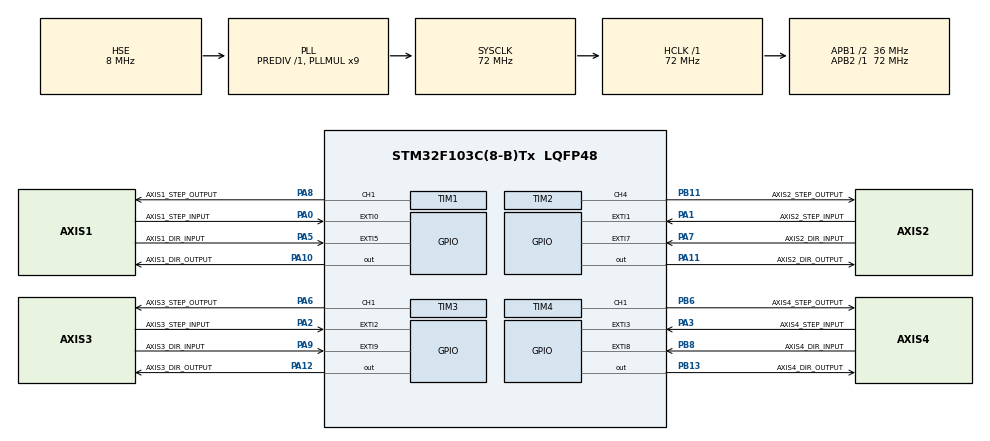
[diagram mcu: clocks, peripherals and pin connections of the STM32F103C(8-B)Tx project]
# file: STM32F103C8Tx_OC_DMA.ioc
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Dma.Request0=TIM3_CH1/TRIG
Dma.Request1=TIM4_CH1
Dma.Request2=TIM1_CH1
Dma.Request3=TIM2_CH2/CH4
Dma.TIM1_CH1.2.Direction=DMA_MEMORY_TO_PERIPH
Dma.TIM1_CH1.2.Instance=DMA1_Channel2
Dma.TIM1_CH1.2.MemDataAlignment=DMA_MDATAALIGN_HALFWORD
Dma.TIM1_CH1.2.MemInc=DMA_MINC_DISABLE
Dma.TIM1_CH1.2.Mode=DMA_NORMAL
Dma.TIM1_CH1.2.PeriphDataAlignment=DMA_PDATAALIGN_HALFWORD
Dma.TIM1_CH1.2.PeriphInc=DMA_PINC_DISABLE
Dma.TIM1_CH1.2.Priority=DMA_PRIORITY_MEDIUM
Dma.TIM2_CH2/CH4.3.Direction=DMA_MEMORY_TO_PERIPH
Dma.TIM2_CH2/CH4.3.Instance=DMA1_Channel7
Dma.TIM2_CH2/CH4.3.MemDataAlignment=DMA_MDATAALIGN_HALFWORD
Dma.TIM2_CH2/CH4.3.MemInc=DMA_MINC_DISABLE
Dma.TIM2_CH2/CH4.3.Mode=DMA_NORMAL
Dma.TIM2_CH2/CH4.3.PeriphDataAlignment=DMA_PDATAALIGN_HALFWORD
Dma.TIM2_CH2/CH4.3.PeriphInc=DMA_PINC_DISABLE
Dma.TIM2_CH2/CH4.3.Priority=DMA_PRIORITY_LOW
Dma.TIM3_CH1/TRIG.0.Direction=DMA_MEMORY_TO_PERIPH
Dma.TIM3_CH1/TRIG.0.Instance=DMA1_Channel6
Dma.TIM3_CH1/TRIG.0.MemDataAlignment=DMA_MDATAALIGN_HALFWORD
Dma.TIM3_CH1/TRIG.0.MemInc=DMA_MINC_DISABLE
Dma.TIM3_CH1/TRIG.0.Mode=DMA_NORMAL
Dma.TIM3_CH1/TRIG.0.PeriphDataAlignment=DMA_PDATAALIGN_HALFWORD
Dma.TIM3_CH1/TRIG.0.PeriphInc=DMA_PINC_DISABLE
Dma.TIM3_CH1/TRIG.0.Priority=DMA_PRIORITY_VERY_HIGH
Dma.TIM4_CH1.1.Direction=DMA_MEMORY_TO_PERIPH
Dma.TIM4_CH1.1.Instance=DMA1_Channel1
Dma.TIM4_CH1.1.MemDataAlignment=DMA_MDATAALIGN_HALFWORD
Dma.TIM4_CH1.1.MemInc=DMA_MINC_DISABLE
Dma.TIM4_CH1.1.Mode=DMA_NORMAL
Dma.TIM4_CH1.1.PeriphDataAlignment=DMA_PDATAALIGN_HALFWORD
Dma.TIM4_CH1.1.PeriphInc=DMA_PINC_DISABLE
Dma.TIM4_CH1.1.Priority=DMA_PRIORITY_HIGH
Mcu.Family=STM32F1
Mcu.Name=STM32F103C(8-B)Tx
Mcu.Package=LQFP48
NVIC.DMA1_Channel1_IRQn=true\:0\:0\:false\:true\:true\:5
NVIC.DMA1_Channel2_IRQn=true\:0\:0\:false\:true\:true\:6
NVIC.DMA1_Channel6_IRQn=true\:0\:0\:false\:true\:true\:7
NVIC.DMA1_Channel7_IRQn=true\:0\:0\:false\:true\:true\:8
NVIC.EXTI0_IRQn=true\:0\:0\:false\:true\:true\:1
NVIC.EXTI1_IRQn=true\:0\:0\:false\:true\:true\:2
NVIC.EXTI2_IRQn=true\:0\:0\:false\:true\:true\:3
NVIC.EXTI3_IRQn=true\:0\:0\:false\:true\:true\:9
NVIC.EXTI9_5_IRQn=true\:0\:0\:false\:true\:true\:4
NVIC.PriorityGroup=NVIC_PRIORITYGROUP_4
PA0-WKUP.GPIO_Label=AXIS1_STEP_INPUT
PA0-WKUP.GPIO_ModeDefaultEXTI=GPIO_MODE_IT_FALLING
PA0-WKUP.GPIO_PuPd=GPIO_PULLDOWN
PA0-WKUP.Signal=GPXTI0
PA1.GPIO_Label=AXIS2_STEP_INPUT
PA1.GPIO_ModeDefaultEXTI=GPIO_MODE_IT_FALLING
PA1.GPIO_PuPd=GPIO_PULLDOWN
PA1.Signal=GPXTI1
PA10.GPIO_Label=AXIS1_DIR_OUTPUT
PA10.GPIO_ModeDefaultOutputPP=GPIO_MODE_OUTPUT_PP
PA10.GPIO_Speed=GPIO_SPEED_FREQ_LOW
PA10.PinState=GPIO_PIN_RESET
PA10.Signal=GPIO_Output
PA11.GPIO_Label=AXIS2_DIR_OUTPUT
PA11.GPIO_ModeDefaultOutputPP=GPIO_MODE_OUTPUT_PP
PA11.GPIO_Speed=GPIO_SPEED_FREQ_LOW
PA11.PinState=GPIO_PIN_RESET
PA11.Signal=GPIO_Output
PA12.GPIO_Label=AXIS3_DIR_OUTPUT
PA12.GPIO_ModeDefaultOutputPP=GPIO_MODE_OUTPUT_PP
PA12.GPIO_Speed=GPIO_SPEED_FREQ_LOW
PA12.PinState=GPIO_PIN_RESET
PA12.Signal=GPIO_Output
PA13.Mode=Serial_Wire
PA13.Signal=SYS_JTMS-SWDIO
PA14.Mode=Serial_Wire
PA14.Signal=SYS_JTCK-SWCLK
PA2.GPIO_Label=AXIS3_STEP_INPUT
PA2.GPIO_ModeDefaultEXTI=GPIO_MODE_IT_FALLING
PA2.GPIO_PuPd=GPIO_PULLDOWN
PA2.Signal=GPXTI2
PA3.GPIO_Label=AXIS4_STEP_INPUT
PA3.GPIO_ModeDefaultEXTI=GPIO_MODE_IT_FALLING
PA3.GPIO_PuPd=GPIO_PULLDOWN
PA3.Signal=GPXTI3
PA5.GPIO_Label=AXIS1_DIR_INPUT
PA5.GPIO_ModeDefaultEXTI=GPIO_MODE_IT_RISING_FALLING
PA5.GPIO_PuPd=GPIO_PULLDOWN
PA5.Signal=GPXTI5
PA6.GPIO_Label=AXIS3_STEP_OUTPUT
PA6.GPIO_Speed=GPIO_SPEED_FREQ_HIGH
PA6.Signal=S_TIM3_CH1
PA7.GPIO_Label=AXIS2_DIR_INPUT
PA7.GPIO_ModeDefaultEXTI=GPIO_MODE_IT_RISING_FALLING
PA7.GPIO_PuPd=GPIO_PULLDOWN
PA7.Signal=GPXTI7
PA8.GPIO_Label=AXIS1_STEP_OUTPUT
PA8.GPIO_Speed=GPIO_SPEED_FREQ_HIGH
PA8.Signal=S_TIM1_CH1
PA9.GPIO_Label=AXIS3_DIR_INPUT
PA9.GPIO_ModeDefaultEXTI=GPIO_MODE_IT_RISING_FALLING
PA9.GPIO_PuPd=GPIO_PULLDOWN
PA9.Signal=GPXTI9
PB11.GPIO_Label=AXIS2_STEP_OUTPUT
PB11.GPIO_ModeDefaultPP=GPIO_MODE_AF_PP
PB11.GPIO_Speed=GPIO_SPEED_FREQ_HIGH
PB11.Signal=S_TIM2_CH4
PB13.GPIO_Label=AXIS4_DIR_OUTPUT
PB13.Signal=GPIO_Output
PB6.GPIO_Label=AXIS4_STEP_OUTPUT
PB6.GPIO_Speed=GPIO_SPEED_FREQ_HIGH
PB6.Signal=S_TIM4_CH1
PB8.GPIO_Label=AXIS4_DIR_INPUT
PB8.GPIO_ModeDefaultEXTI=GPIO_MODE_IT_RISING_FALLING
PB8.GPIO_PuPd=GPIO_PULLDOWN
PB8.Signal=GPXTI8
PD0-OSC_IN.Mode=HSE-External-Oscillator
PD0-OSC_IN.Signal=RCC_OSC_IN
PD1-OSC_OUT.Mode=HSE-External-Oscillator
PD1-OSC_OUT.Signal=RCC_OSC_OUT
ProjectManager.HeapSize=0x200
ProjectManager.StackSize=0x400
ProjectManager.TargetToolchain=SW4STM32
RCC.AHBCLKDivider=RCC_SYSCLK_DIV1
RCC.AHBFreq_Value=72000000
RCC.APB1CLKDivider=RCC_HCLK_DIV2
RCC.APB1Freq_Value=36000000
RCC.APB1TimFreq_Value=72000000
RCC.APB2CLKDivider=RCC_HCLK_DIV1
RCC.APB2Freq_Value=72000000
RCC.APB2TimFreq_Value=72000000
RCC.HCLKFreq_Value=72000000
RCC.OscillatorTypeHSI=RCC_OSCILLATORTYPE_HSI
RCC.PLLMUL=RCC_PLL_MUL9
RCC.PLLSourceVirtual=RCC_PLLSOURCE_HSE
RCC.SYSCLKFreq_VALUE=72000000
RCC.SYSCLKSource=RCC_SYSCLKSOURCE_PLLCLK
RCC.TimSys_Div=SYSTICK_CLKSOURCE_HCLK
RCC.USBFreq_Value=72000000
SH.S_TIM1_CH1.0=TIM1_CH1,Output Compare1 CH1
SH.S_TIM2_CH4.0=TIM2_CH4,Output Compare4 CH4
SH.S_TIM3_CH1.0=TIM3_CH1,Output Compare1 CH1
SH.S_TIM4_CH1.0=TIM4_CH1,Output Compare1 CH1
TIM1.Channel-Output\ Compare1\ CH1=TIM_CHANNEL_1
TIM1.OCIdleState_1=TIM_OCIDLESTATE_RESET
TIM1.OCMode_1=TIM_OCMODE_TOGGLE
TIM1.OCPolarity_1=TIM_OCPOLARITY_HIGH
TIM1.Period=0xFFFF
TIM1.Prescaler=0xFFFF
TIM1.Pulse-Output\ Compare1\ CH1=0xFFFF
TIM1.TIM_MasterOutputTrigger=TIM_TRGO_RESET
TIM2.Channel-Output\ Compare4\ CH4=TIM_CHANNEL_4
TIM2.OCMode_4=TIM_OCMODE_TOGGLE
TIM2.OCPolarity_4=TIM_OCPOLARITY_HIGH
TIM2.Period=0xFFFF
TIM2.Prescaler=0xFFFF
TIM2.Pulse-Output\ Compare4\ CH4=0xFFFF
TIM2.TIM_MasterOutputTrigger=TIM_TRGO_RESET
TIM3.Channel-Output\ Compare1\ CH1=TIM_CHANNEL_1
TIM3.OCMode_1=TIM_OCMODE_TOGGLE
TIM3.OCPolarity_1=TIM_OCPOLARITY_HIGH
TIM3.Period=0xFFFF
TIM3.Prescaler=0xFFFF
TIM3.Pulse-Output\ Compare1\ CH1=0xFFFF
TIM3.TIM_MasterOutputTrigger=TIM_TRGO_RESET
TIM4.Channel-Output\ Compare1\ CH1=TIM_CHANNEL_1
TIM4.OCMode_1=TIM_OCMODE_TOGGLE
TIM4.OCPolarity_1=TIM_OCPOLARITY_HIGH
TIM4.Period=0xFFFF
TIM4.Prescaler=0xFFFF
TIM4.Pulse-Output\ Compare1\ CH1=0xFFFF
TIM4.TIM_MasterOutputTrigger=TIM_TRGO_RESET
VP_TIM1_VS_ClockSourceINT.Mode=Internal
VP_TIM2_VS_ClockSourceINT.Mode=Internal
VP_TIM3_VS_ClockSourceINT.Mode=Internal
VP_TIM4_VS_ClockSourceINT.Mode=Internal
board=STM32F103C8Tx_OC_DMA

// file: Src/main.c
/**
  ******************************************************************************
  * File Name          : main.c
  * Description        : Main program body
  ******************************************************************************
  ** This notice applies to any and all portions of this file
  * that are not between comment pairs USER CODE BEGIN and
  * USER CODE END. Other portions of this file, whether
  * inserted by the user or by software development tools
  * are owned by their respective copyright owners.
  *
  * COPYRIGHT(c) 2017 STMicroelectronics
  *
  * Redistribution and use in source and binary forms, with or without modification,
  * are permitted provided that the following conditions are met:
  *   1. Redistributions of source code must retain the above copyright notice,
  *      this list of conditions and the following disclaimer.
  *   2. Redistributions in binary form must reproduce the above copyright notice,
  *      this list of conditions and the following disclaimer in the documentation
  *      and/or other materials provided with the distribution.
  *   3. Neither the name of STMicroelectronics nor the names of its contributors
  *      may be used to endorse or promote products derived from this software
  *      without specific prior written permission.
  *
  * THIS SOFTWARE IS PROVIDED BY THE COPYRIGHT HOLDERS AND CONTRIBUTORS "AS IS"
  * AND ANY EXPRESS OR IMPLIED WARRANTIES, INCLUDING, BUT NOT LIMITED TO, THE
  * IMPLIED WARRANTIES OF MERCHANTABILITY AND FITNESS FOR A PARTICULAR PURPOSE ARE
  * DISCLAIMED. IN NO EVENT SHALL THE COPYRIGHT HOLDER OR CONTRIBUTORS BE LIABLE
  * FOR ANY DIRECT, INDIRECT, INCIDENTAL, SPECIAL, EXEMPLARY, OR CONSEQUENTIAL
  * DAMAGES (INCLUDING, BUT NOT LIMITED TO, PROCUREMENT OF SUBSTITUTE GOODS OR
  * SERVICES; LOSS OF USE, DATA, OR PROFITS; OR BUSINESS INTERRUPTION) HOWEVER
  * CAUSED AND ON ANY THEORY OF LIABILITY, WHETHER IN CONTRACT, STRICT LIABILITY,
  * OR TORT (INCLUDING NEGLIGENCE OR OTHERWISE) ARISING IN ANY WAY OUT OF THE USE
  * OF THIS SOFTWARE, EVEN IF ADVISED OF THE POSSIBILITY OF SUCH DAMAGE.
  *
  ******************************************************************************
  */
#include "main.h"
#include "stm32f1xx_hal.h"

TIM_HandleTypeDef htim1;
TIM_HandleTypeDef htim2;
TIM_HandleTypeDef htim3;
TIM_HandleTypeDef htim4;
DMA_HandleTypeDef hdma_tim1_ch1;
DMA_HandleTypeDef hdma_tim2_ch2_ch4;
DMA_HandleTypeDef hdma_tim3_ch1_trig;
DMA_HandleTypeDef hdma_tim4_ch1;

void SystemClock_Config(void);
static void MX_GPIO_Init(void);
static void MX_DMA_Init(void);
static void MX_TIM1_Init(void);
static void MX_TIM2_Init(void);
static void MX_TIM3_Init(void);
static void MX_TIM4_Init(void);
static void MX_NVIC_Init(void);
void HAL_TIM_MspPostInit(TIM_HandleTypeDef *htim);

/* USER CODE BEGIN PFP */
void setup_out_timers_2();
/* USER CODE END PFP */

int main(void)
{

  /* MCU Configuration----------------------------------------------------------*/

  /* Reset of all peripherals, Initializes the Flash interface and the Systick. */
  HAL_Init();

  /* Configure the system clock */
  SystemClock_Config();

  /* Initialize all configured peripherals */
  MX_GPIO_Init();
  MX_DMA_Init();
  MX_TIM1_Init();
  MX_TIM2_Init();
  MX_TIM3_Init();
  MX_TIM4_Init();

  /* Initialize interrupts */
  MX_NVIC_Init();

  /* USER CODE BEGIN 2 */
  setup_out_timers_2();
  /* USER CODE END 2 */

  /* Infinite loop */
  while (1)
  {

  }

}

/** System Clock Configuration
*/
void SystemClock_Config(void)
{

  RCC_OscInitTypeDef RCC_OscInitStruct;
  RCC_ClkInitTypeDef RCC_ClkInitStruct;

    /**Initializes the CPU, AHB and APB busses clocks
    */
  RCC_OscInitStruct.OscillatorType = RCC_OSCILLATORTYPE_HSI|RCC_OSCILLATORTYPE_HSE;
  RCC_OscInitStruct.HSEState = RCC_HSE_ON;
  RCC_OscInitStruct.HSEPredivValue = RCC_HSE_PREDIV_DIV1;
  RCC_OscInitStruct.HSIState = RCC_HSI_ON;
  RCC_OscInitStruct.PLL.PLLState = RCC_PLL_ON;
  RCC_OscInitStruct.PLL.PLLSource = RCC_PLLSOURCE_HSE;
  RCC_OscInitStruct.PLL.PLLMUL = RCC_PLL_MUL9;
  if (HAL_RCC_OscConfig(&RCC_OscInitStruct) != HAL_OK)
  {
    _Error_Handler(__FILE__, __LINE__);
  }

    /**Initializes the CPU, AHB and APB busses clocks
    */
  RCC_ClkInitStruct.ClockType = RCC_CLOCKTYPE_HCLK|RCC_CLOCKTYPE_SYSCLK
                              |RCC_CLOCKTYPE_PCLK1|RCC_CLOCKTYPE_PCLK2;
  RCC_ClkInitStruct.SYSCLKSource = RCC_SYSCLKSOURCE_PLLCLK;
  RCC_ClkInitStruct.AHBCLKDivider = RCC_SYSCLK_DIV1;
  RCC_ClkInitStruct.APB1CLKDivider = RCC_HCLK_DIV2;
  RCC_ClkInitStruct.APB2CLKDivider = RCC_HCLK_DIV1;

  if (HAL_RCC_ClockConfig(&RCC_ClkInitStruct, FLASH_LATENCY_2) != HAL_OK)
  {
    _Error_Handler(__FILE__, __LINE__);
  }

    /**Configure the Systick interrupt time
    */
  HAL_SYSTICK_Config(HAL_RCC_GetHCLKFreq()/1000);

    /**Configure the Systick
    */
  HAL_SYSTICK_CLKSourceConfig(SYSTICK_CLKSOURCE_HCLK);

  /* SysTick_IRQn interrupt configuration */
  HAL_NVIC_SetPriority(SysTick_IRQn, 0, 0);
}

/** NVIC Configuration
*/
static void MX_NVIC_Init(void)
{
  /* EXTI0_IRQn interrupt configuration */
  HAL_NVIC_SetPriority(EXTI0_IRQn, 0, 0);
  HAL_NVIC_EnableIRQ(EXTI0_IRQn);
  /* EXTI1_IRQn interrupt configuration */
  HAL_NVIC_SetPriority(EXTI1_IRQn, 0, 0);
  HAL_NVIC_EnableIRQ(EXTI1_IRQn);
  /* EXTI2_IRQn interrupt configuration */
  HAL_NVIC_SetPriority(EXTI2_IRQn, 0, 0);
  HAL_NVIC_EnableIRQ(EXTI2_IRQn);
  /* EXTI9_5_IRQn interrupt configuration */
  HAL_NVIC_SetPriority(EXTI9_5_IRQn, 0, 0);
  HAL_NVIC_EnableIRQ(EXTI9_5_IRQn);
  /* DMA1_Channel1_IRQn interrupt configuration */
  HAL_NVIC_SetPriority(DMA1_Channel1_IRQn, 0, 0);
  HAL_NVIC_EnableIRQ(DMA1_Channel1_IRQn);
  /* DMA1_Channel2_IRQn interrupt configuration */
  HAL_NVIC_SetPriority(DMA1_Channel2_IRQn, 0, 0);
  HAL_NVIC_EnableIRQ(DMA1_Channel2_IRQn);
  /* DMA1_Channel6_IRQn interrupt configuration */
  HAL_NVIC_SetPriority(DMA1_Channel6_IRQn, 0, 0);
  HAL_NVIC_EnableIRQ(DMA1_Channel6_IRQn);
  /* DMA1_Channel7_IRQn interrupt configuration */
  HAL_NVIC_SetPriority(DMA1_Channel7_IRQn, 0, 0);
  HAL_NVIC_EnableIRQ(DMA1_Channel7_IRQn);
  /* EXTI3_IRQn interrupt configuration */
  HAL_NVIC_SetPriority(EXTI3_IRQn, 0, 0);
  HAL_NVIC_EnableIRQ(EXTI3_IRQn);
}

/* TIM1 init function */
static void MX_TIM1_Init(void)
{

  TIM_ClockConfigTypeDef sClockSourceConfig;
  TIM_MasterConfigTypeDef sMasterConfig;
  TIM_OC_InitTypeDef sConfigOC;
  TIM_BreakDeadTimeConfigTypeDef sBreakDeadTimeConfig;

  htim1.Instance = TIM1;
  htim1.Init.Prescaler = 0xFFFF;
  htim1.Init.CounterMode = TIM_COUNTERMODE_UP;
  htim1.Init.Period = 0xFFFF;
  htim1.Init.ClockDivision = TIM_CLOCKDIVISION_DIV1;
  htim1.Init.RepetitionCounter = 0;
  if (HAL_TIM_Base_Init(&htim1) != HAL_OK)
  {
    _Error_Handler(__FILE__, __LINE__);
  }

  sClockSourceConfig.ClockSource = TIM_CLOCKSOURCE_INTERNAL;
  if (HAL_TIM_ConfigClockSource(&htim1, &sClockSourceConfig) != HAL_OK)
  {
    _Error_Handler(__FILE__, __LINE__);
  }

  if (HAL_TIM_OC_Init(&htim1) != HAL_OK)
  {
    _Error_Handler(__FILE__, __LINE__);
  }

  sMasterConfig.MasterOutputTrigger = TIM_TRGO_RESET;
  sMasterConfig.MasterSlaveMode = TIM_MASTERSLAVEMODE_DISABLE;
  if (HAL_TIMEx_MasterConfigSynchronization(&htim1, &sMasterConfig) != HAL_OK)
  {
    _Error_Handler(__FILE__, __LINE__);
  }

  sConfigOC.OCMode = TIM_OCMODE_TOGGLE;
  sConfigOC.Pulse = 0xFFFF;
  sConfigOC.OCPolarity = TIM_OCPOLARITY_HIGH;
  sConfigOC.OCNPolarity = TIM_OCNPOLARITY_HIGH;
  sConfigOC.OCFastMode = TIM_OCFAST_DISABLE;
  sConfigOC.OCIdleState = TIM_OCIDLESTATE_RESET;
  sConfigOC.OCNIdleState = TIM_OCNIDLESTATE_RESET;
  if (HAL_TIM_OC_ConfigChannel(&htim1, &sConfigOC, TIM_CHANNEL_1) != HAL_OK)
  {
    _Error_Handler(__FILE__, __LINE__);
  }

  sBreakDeadTimeConfig.OffStateRunMode = TIM_OSSR_DISABLE;
  sBreakDeadTimeConfig.OffStateIDLEMode = TIM_OSSI_DISABLE;
  sBreakDeadTimeConfig.LockLevel = TIM_LOCKLEVEL_OFF;
  sBreakDeadTimeConfig.DeadTime = 0;
  sBreakDeadTimeConfig.BreakState = TIM_BREAK_DISABLE;
  sBreakDeadTimeConfig.BreakPolarity = TIM_BREAKPOLARITY_HIGH;
  sBreakDeadTimeConfig.AutomaticOutput = TIM_AUTOMATICOUTPUT_DISABLE;
  if (HAL_TIMEx_ConfigBreakDeadTime(&htim1, &sBreakDeadTimeConfig) != HAL_OK)
  {
    _Error_Handler(__FILE__, __LINE__);
  }

  HAL_TIM_MspPostInit(&htim1);

}

/* TIM2 init function */
static void MX_TIM2_Init(void)
{

  TIM_ClockConfigTypeDef sClockSourceConfig;
  TIM_MasterConfigTypeDef sMasterConfig;
  TIM_OC_InitTypeDef sConfigOC;

  htim2.Instance = TIM2;
  htim2.Init.Prescaler = 0xFFFF;
  htim2.Init.CounterMode = TIM_COUNTERMODE_UP;
  htim2.Init.Period = 0xFFFF;
  htim2.Init.ClockDivision = TIM_CLOCKDIVISION_DIV1;
  if (HAL_TIM_Base_Init(&htim2) != HAL_OK)
  {
    _Error_Handler(__FILE__, __LINE__);
  }

  sClockSourceConfig.ClockSource = TIM_CLOCKSOURCE_INTERNAL;
  if (HAL_TIM_ConfigClockSource(&htim2, &sClockSourceConfig) != HAL_OK)
  {
    _Error_Handler(__FILE__, __LINE__);
  }

  if (HAL_TIM_OC_Init(&htim2) != HAL_OK)
  {
    _Error_Handler(__FILE__, __LINE__);
  }

  sMasterConfig.MasterOutputTrigger = TIM_TRGO_RESET;
  sMasterConfig.MasterSlaveMode = TIM_MASTERSLAVEMODE_DISABLE;
  if (HAL_TIMEx_MasterConfigSynchronization(&htim2, &sMasterConfig) != HAL_OK)
  {
    _Error_Handler(__FILE__, __LINE__);
  }

  sConfigOC.OCMode = TIM_OCMODE_TOGGLE;
  sConfigOC.Pulse = 0xFFFF;
  sConfigOC.OCPolarity = TIM_OCPOLARITY_HIGH;
  sConfigOC.OCFastMode = TIM_OCFAST_DISABLE;
  if (HAL_TIM_OC_ConfigChannel(&htim2, &sConfigOC, TIM_CHANNEL_4) != HAL_OK)
  {
    _Error_Handler(__FILE__, __LINE__);
  }

  HAL_TIM_MspPostInit(&htim2);

}

/* TIM3 init function */
static void MX_TIM3_Init(void)
{

  TIM_ClockConfigTypeDef sClockSourceConfig;
  TIM_MasterConfigTypeDef sMasterConfig;
  TIM_OC_InitTypeDef sConfigOC;

  htim3.Instance = TIM3;
  htim3.Init.Prescaler = 0xFFFF;
  htim3.Init.CounterMode = TIM_COUNTERMODE_UP;
  htim3.Init.Period = 0xFFFF;
  htim3.Init.ClockDivision = TIM_CLOCKDIVISION_DIV1;
  if (HAL_TIM_Base_Init(&htim3) != HAL_OK)
  {
    _Error_Handler(__FILE__, __LINE__);
  }

  sClockSourceConfig.ClockSource = TIM_CLOCKSOURCE_INTERNAL;
  if (HAL_TIM_ConfigClockSource(&htim3, &sClockSourceConfig) != HAL_OK)
  {
    _Error_Handler(__FILE__, __LINE__);
  }

  if (HAL_TIM_OC_Init(&htim3) != HAL_OK)
  {
    _Error_Handler(__FILE__, __LINE__);
  }

  sMasterConfig.MasterOutputTrigger = TIM_TRGO_RESET;
  sMasterConfig.MasterSlaveMode = TIM_MASTERSLAVEMODE_DISABLE;
  if (HAL_TIMEx_MasterConfigSynchronization(&htim3, &sMasterConfig) != HAL_OK)
  {
    _Error_Handler(__FILE__, __LINE__);
  }

  sConfigOC.OCMode = TIM_OCMODE_TOGGLE;
  sConfigOC.Pulse = 0xFFFF;
  sConfigOC.OCPolarity = TIM_OCPOLARITY_HIGH;
  sConfigOC.OCFastMode = TIM_OCFAST_DISABLE;
  if (HAL_TIM_OC_ConfigChannel(&htim3, &sConfigOC, TIM_CHANNEL_1) != HAL_OK)
  {
    _Error_Handler(__FILE__, __LINE__);
  }

  HAL_TIM_MspPostInit(&htim3);

}

/* TIM4 init function */
static void MX_TIM4_Init(void)
{

  TIM_ClockConfigTypeDef sClockSourceConfig;
  TIM_MasterConfigTypeDef sMasterConfig;
  TIM_OC_InitTypeDef sConfigOC;

  htim4.Instance = TIM4;
  htim4.Init.Prescaler = 0xFFFF;
  htim4.Init.CounterMode = TIM_COUNTERMODE_UP;
  htim4.Init.Period = 0xFFFF;
  htim4.Init.ClockDivision = TIM_CLOCKDIVISION_DIV1;
  if (HAL_TIM_Base_Init(&htim4) != HAL_OK)
  {
    _Error_Handler(__FILE__, __LINE__);
  }

  sClockSourceConfig.ClockSource = TIM_CLOCKSOURCE_INTERNAL;
  if (HAL_TIM_ConfigClockSource(&htim4, &sClockSourceConfig) != HAL_OK)
  {
    _Error_Handler(__FILE__, __LINE__);
  }

  if (HAL_TIM_OC_Init(&htim4) != HAL_OK)
  {
    _Error_Handler(__FILE__, __LINE__);
  }

  sMasterConfig.MasterOutputTrigger = TIM_TRGO_RESET;
  sMasterConfig.MasterSlaveMode = TIM_MASTERSLAVEMODE_DISABLE;
  if (HAL_TIMEx_MasterConfigSynchronization(&htim4, &sMasterConfig) != HAL_OK)
  {
    _Error_Handler(__FILE__, __LINE__);
  }

  sConfigOC.OCMode = TIM_OCMODE_TOGGLE;
  sConfigOC.Pulse = 0xFFFF;
  sConfigOC.OCPolarity = TIM_OCPOLARITY_HIGH;
  sConfigOC.OCFastMode = TIM_OCFAST_DISABLE;
  if (HAL_TIM_OC_ConfigChannel(&htim4, &sConfigOC, TIM_CHANNEL_1) != HAL_OK)
  {
    _Error_Handler(__FILE__, __LINE__);
  }

  HAL_TIM_MspPostInit(&htim4);

}

static void MX_DMA_Init(void)
{
  /* DMA controller clock enable */
  __HAL_RCC_DMA1_CLK_ENABLE();

}

/** Configure pins as
        * Analog
        * Input
        * Output
        * EVENT_OUT
        * EXTI
*/
static void MX_GPIO_Init(void)
{

  GPIO_InitTypeDef GPIO_InitStruct;

  /* GPIO Ports Clock Enable */
  __HAL_RCC_GPIOD_CLK_ENABLE();
  __HAL_RCC_GPIOA_CLK_ENABLE();
  __HAL_RCC_GPIOB_CLK_ENABLE();

  /*Configure GPIO pin Output Level */
  HAL_GPIO_WritePin(AXIS4_DIR_OUTPUT_GPIO_Port, AXIS4_DIR_OUTPUT_Pin, GPIO_PIN_RESET);

  /*Configure GPIO pin Output Level */
  HAL_GPIO_WritePin(GPIOA, AXIS1_DIR_OUTPUT_Pin|AXIS2_DIR_OUTPUT_Pin|AXIS3_DIR_OUTPUT_Pin, GPIO_PIN_RESET);

  /*Configure GPIO pins : AXIS1_STEP_INPUT_Pin AXIS2_STEP_INPUT_Pin AXIS3_STEP_INPUT_Pin AXIS4_STEP_INPUT_Pin */
  GPIO_InitStruct.Pin = AXIS1_STEP_INPUT_Pin|AXIS2_STEP_INPUT_Pin|AXIS3_STEP_INPUT_Pin|AXIS4_STEP_INPUT_Pin;
  GPIO_InitStruct.Mode = GPIO_MODE_IT_FALLING;
  GPIO_InitStruct.Pull = GPIO_PULLDOWN;
  HAL_GPIO_Init(GPIOA, &GPIO_InitStruct);

  /*Configure GPIO pins : AXIS1_DIR_INPUT_Pin AXIS2_DIR_INPUT_Pin AXIS3_DIR_INPUT_Pin */
  GPIO_InitStruct.Pin = AXIS1_DIR_INPUT_Pin|AXIS2_DIR_INPUT_Pin|AXIS3_DIR_INPUT_Pin;
  GPIO_InitStruct.Mode = GPIO_MODE_IT_RISING_FALLING;
  GPIO_InitStruct.Pull = GPIO_PULLDOWN;
  HAL_GPIO_Init(GPIOA, &GPIO_InitStruct);

  /*Configure GPIO pin : AXIS4_DIR_OUTPUT_Pin */
  GPIO_InitStruct.Pin = AXIS4_DIR_OUTPUT_Pin;
  GPIO_InitStruct.Mode = GPIO_MODE_OUTPUT_PP;
  GPIO_InitStruct.Speed = GPIO_SPEED_FREQ_LOW;
  HAL_GPIO_Init(AXIS4_DIR_OUTPUT_GPIO_Port, &GPIO_InitStruct);

  /*Configure GPIO pins : AXIS1_DIR_OUTPUT_Pin AXIS2_DIR_OUTPUT_Pin AXIS3_DIR_OUTPUT_Pin */
  GPIO_InitStruct.Pin = AXIS1_DIR_OUTPUT_Pin|AXIS2_DIR_OUTPUT_Pin|AXIS3_DIR_OUTPUT_Pin;
  GPIO_InitStruct.Mode = GPIO_MODE_OUTPUT_PP;
  GPIO_InitStruct.Speed = GPIO_SPEED_FREQ_LOW;
  HAL_GPIO_Init(GPIOA, &GPIO_InitStruct);

  /*Configure GPIO pin : AXIS4_DIR_INPUT_Pin */
  GPIO_InitStruct.Pin = AXIS4_DIR_INPUT_Pin;
  GPIO_InitStruct.Mode = GPIO_MODE_IT_RISING_FALLING;
  GPIO_InitStruct.Pull = GPIO_PULLDOWN;
  HAL_GPIO_Init(AXIS4_DIR_INPUT_GPIO_Port, &GPIO_InitStruct);

}

void _Error_Handler(char * file, int line)
{
  while(1)
  {
  }
}

/************************ (C) COPYRIGHT STMicroelectronics *****END OF FILE****/
